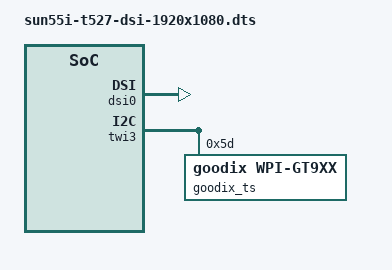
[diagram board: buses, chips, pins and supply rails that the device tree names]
/dts-v1/;
/plugin/;

/ {
	fragment@0 {
		target-path = "/";
		__overlay__ {
			panel_dsi: panel_dsi {
				power0-supply = <&reg_dcdc4>;
				status = "okay";
				backlight = <&backlight0>;
				dsi,flags = <1>;
				dsi,lanes = <4>;
				dsi,format = <0>;
				
				panel-init-sequence = [
				39 00 04 df 95 22 b7
				39 00 08 b0 01 23 06 88 65 06 00
				39 00 03 b2 01 1d
				39 00 03 b3 01 1d
				39 00 07 b7 00 e0 00 00 e0 00
				39 00 04 cf 49 24 3f
				39 00 05 b9 22 fc 33 00
				39 00 03 c0 04 04
				39 00 04 c1 00 10 00
				39 00 17 c3 3c 01 01 01 01 09 1d 20 34 37 4b 08 03 03 03 02 01 01 01 01 01 4f
				39 00 06 c4 36 c0 56 08 07
				39 00 09 bb 01 01 24 6a 0a 46 14 05
				39 00 30 c8 00 ff f9 f5 e9 df ce d7 c2 ba 9b a7 9d 92 83 65 78 64 5b 4a 34 26 20 1e ff f9 f5 e9 df ce d7 c2 ba 9b a7 9d 92 83 65 78 64 5b 4a 34 26 20 1e
				39 00 30 c9 00 ff f9 f5 e9 df ce d7 c2 ba 9b a7 9d 92 83 65 78 64 5b 4a 34 26 20 1e ff f9 f5 e9 df ce d7 c2 ba 9b a7 9d 92 83 65 78 64 5b 4a 34 26 20 1e
				39 00 30 ca 00 ff f9 f5 e9 df ce d7 c2 ba 9b a7 9d 92 83 65 78 64 5b 4a 34 26 20 1e ff f9 f5 e9 df ce d7 c2 ba 9b a7 9d 92 83 65 78 64 5b 4a 34 26 20 1e
				39 00 16 d0 00 1f 1e 1f 01 05 0b 09 07 1f 1f 1f 21 22 23 1f 1f 38 00 38 01
				39 00 16 d1 00 1f 1e 1f 00 04 0a 08 06 1f 1f 1f 21 22 23 1f 1f 38 00 38 01
				39 00 16 d2 00 1f 1e 1f 00 06 08 0a 04 1f 1f 1f 21 22 23 1f 1f 38 00 38 01
				39 00 16 d3 00 1f 1e 1f 01 07 09 0b 05 1f 1f 1f 21 22 23 1f 1f 38 00 38 01
				39 00 21 d4 01 07 80 15 05 00 01 02 04 50 37 87 30 01 02 01 49 70 06 04 4f 06 00 01 00 00 01 00 00 06 02 02
				39 00 22 d5 00 00 00 00 00 00 00 80 00 00 01 49 00 07 50 00 77 99 00 49 a0 1f 00 00 00 06 03 c0 00 02 06 08 08
				39 00 03 be 5a 62
				39 00 05 dd 2a a3 2a e9
				39 00 02 de 02
				39 00 09 c2 00 20 38 38 9f 43 98 00
				39 00 03 c1 04 14
				39 00 04 cf 00 00 04
				39 00 02 de 03
				39 00 02 c7 50
				39 00 02 de 00
				39 00 01 35
				39 00 01 11
				39 ff 01 29
				];
				
				panel-exit-sequence = [
				
				];
				
				display-timings {
					native-mode = <&timing0>;
					timing0: timing0 {
						clock-frequency = <139392000>;
						hback-porch = <20>;
						hactive = <1080>;
						hfront-porch = <80>;
						hsync-len = <20>;
						vback-porch = <6>;
						vactive = <1920>;
						vfront-porch = <8>;
						vsync-len = <2>;
					};
				};
				
				
			};
		};
	};
	fragment@1 {
		target = <&dsi0>;
		__overlay__ {
			#address-cells = <1>;
			#size-cells = <0>;
			status = "okay";
			
		};
	};
	fragment@2 {
		target = <&twi3>;
		__overlay__ {
			#address-cells = <1>;
			#size-cells = <0>;
			goodix_ts@5d {
				compatible = "goodix,wpi-gt9xx";
				reg = <0x5d>;// I2C地址
				status = "okay";
			
				// interrupt-parent = <&msm_gpio>;
				// interrupts = <13 0x2800>;
				// pinctrl-names = "default", "int-output-low","int-output-high", "int-input";
				// pinctrl-0 = <&ts_int_default>;
				// pinctrl-1 = <&ts_int_output_low>;
				// pinctrl-2 = <&ts_int_output_high>;
				// pinctrl-3 = <&ts_int_input>;
			
				// reset-gpios = <&msm_gpio 12 0x0>;
				// irq-gpios = <&msm_gpio 13 0x2800>;
				// irq-flags = <2>;
			
				touchscreen-max-id = <11>;
				touchscreen-size-x = <1080>;
				touchscreen-size-y = <1920>;
				touchscreen-max-w = <512>;
				touchscreen-max-p = <512>;
				touchscreen-key-map = <172>, <158>; /*KEY_HOMEPAGE=172, KEY_BACK=158，KEY_MENU=139*/
			
				goodix,slide-wakeup = <0>;
				goodix,type-a-report = <0>;
				goodix,driver-send-cfg = <0>;
				goodix,send-cfg-id = <0>;
				goodix,resume-in-workqueue = <0>;
				goodix,int-sync = <1>;
				goodix,swap-x2y = <0>;
				goodix,revert_x = <0>;
				goodix,revert_y = <0>;
				goodix,esd-protect = <0>;
				goodix,auto-update-cfg = <0>;
				goodix,power-off-sleep = <0>;
				goodix,pen-suppress-finger = <0>;
				goodix,cfg-group0 = [
				53 D0 02 00 05 05 F5 D5 21 48 2D 0F 5A 41 0E 05 00 00 32 32 20 00 05 14 14 1A 14 8B 2B 00
				];
			}; 
			
			
			// ft5406: ts@38 {
			// 	compatible = "edt,rpi-ft5506";
			// 	reg = <0x38>;
			// 	touchscreen-size-x = < 800 >;
			// 	touchscreen-size-y = < 480 >;
			// };
			// reg_display: reg_display@45 {
			// 	compatible = "raspberrypi,7inch-touchscreen-panel-regulator";
			// 	reg = <0x45>;
			// 	gpio-controller;
			// 	#gpio-cells = <2>;
			// };
		};
	};
};

